# ATSAMA5D34 register map
Vendor: Atmel; Series: SAMA5D3; File version: 20130221
Registers are 32-bit, read-write, reset 0x0 unless marked. A register's access mark holds for its fields unless they carry their own. Offsets are from the block's base; [hi:lo] are bit positions; {n}, {i} and the like mark numbered series.

## TRNG — True Random Number Generator
Base 0xF8040000; register names take the prefix TRNG_
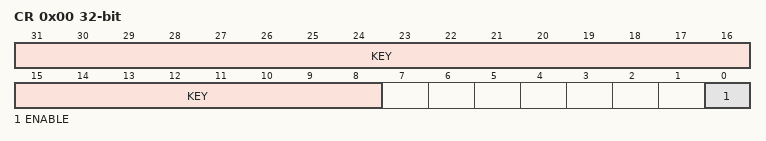
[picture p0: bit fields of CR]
0x00 CR wo reset not defined — Control Register
  [31:8] KEY — Security Key
  [0] ENABLE — Enables the TRNG to provide random values
0x10 IER wo reset not defined — Interrupt Enable Register
  [0] DATRDY — Data Ready Interrupt Enable
0x14 IDR wo reset not defined — Interrupt Disable Register
  [0] DATRDY — Data Ready Interrupt Disable
0x18 IMR ro — Interrupt Mask Register
  [0] DATRDY — Data Ready Interrupt Mask
0x1C ISR ro — Interrupt Status Register
  [0] DATRDY — Data Ready
0x50 ODATA ro — Output Data Register
  [31:0] ODATA — Output Data

## FUSE — Fuse Controller
Base 0xFFFFE400; register names take the prefix FUSE_
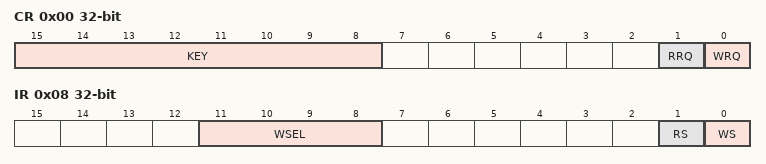
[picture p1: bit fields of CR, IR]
0x00 CR wo reset not defined — Fuse Control Register
  [15:8] KEY — Key code
    251=VALID (valid key.)
  [1] RRQ — Read Request
  [0] WRQ — Write Request
0x04 MR wo reset not defined — Fuse Mode Register
  [0] MSK — Mask Fuse Status Registers
0x08 IR — Fuse Index Register
  [11:8] WSEL — Word Selection
  [1] RS — Read Status
  [0] WS — Write Status
0x0C DR reset not defined — Fuse Data Register
  [31:0] DATA — Data to Program
{0x10+4i} SR[{i}] (i=0..7) ro reset not defined — Fuse Status Register
  [31:0] FUSE — Fuse Status

## MATRIX — AHB Bus Matrix
Base 0xFFFFEC00; register names take the prefix MATRIX_
{0x0+4i} MCFG[{i}] (i=0..15) reset not defined — Master Configuration Register
  [2:0] ULBT — Undefined Length Burst Type
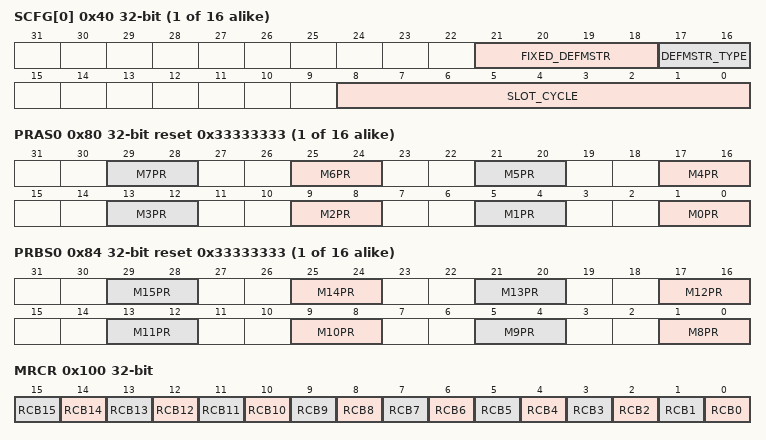
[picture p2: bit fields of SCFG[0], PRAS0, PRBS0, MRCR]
{0x40+4i} SCFG[{i}] (i=0..15) reset not defined — Slave Configuration Register
  [21:18] FIXED_DEFMSTR — Fixed Default Master
  [17:16] DEFMSTR_TYPE — Default Master Type
  [8:0] SLOT_CYCLE — Maximum Bus Grant Duration for Masters
{0x80+8i} PRAS{i} reset 0x33333333 (i=0..15) — Priority Register A for Slave {i}
  [4n+1:4n] M{n}PR (n=0..7) — Master {n} Priority
{0x84+8i} PRBS{i} reset 0x33333333 (i=0..15) — Priority Register B for Slave {i}
  [4n-31:4n-32] M{n}PR (n=8..15) — Master {n} Priority
0x100 MRCR — Master Remap Control Register
  [n] RCB{n} (n=0..15)
{0x110+4i} SFR[{i}] (i=0..15) reset not defined — Special Function Register
  [31:0] SFR — Special Function Register Fields
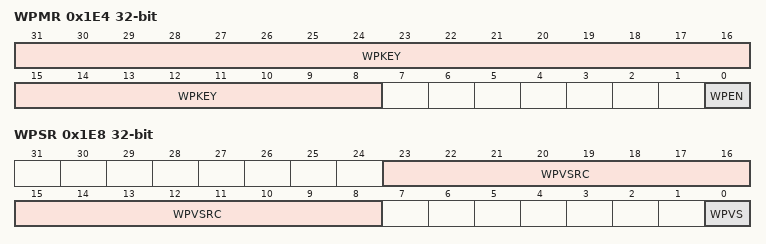
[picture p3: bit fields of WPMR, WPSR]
0x1E4 WPMR — Write Protect Mode Register
  [31:8] WPKEY — Write Protect KEY (Write-only)
  [0] WPEN — Write Protect Enable
0x1E8 WPSR ro — Write Protect Status Register
  [23:8] WPVSRC — Write Protect Violation Source
  [0] WPVS — Write Protect Violation Status

## AIC — Advanced Interrupt Controller
Base 0xFFFFF000; register names take the prefix AIC_
0x00 SSR — Source Select Register
  [6:0] INTSEL — Interrupt line Selection
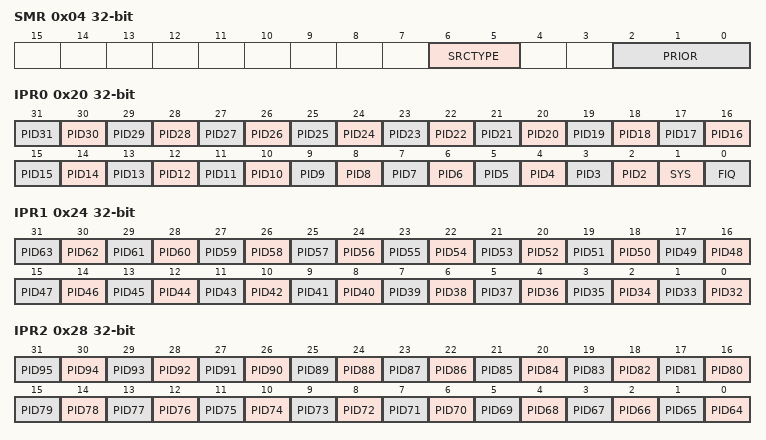
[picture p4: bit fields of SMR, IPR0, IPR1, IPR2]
0x04 SMR — Source Mode Register
  [6:5] SRCTYPE — Interrupt Source Type
    0=INT_LEVEL_SENSITIVE (High level Sensitive for internal sourceLow level Sensitive for external source); 1=INT_EDGE_TRIGGERED (Positive edge triggered for internal sourceNegative edge triggered for external source); 2=EXT_HIGH_LEVEL (High level Sensitive for internal sourceHigh level Sensitive for external source); 3=EXT_POSITIVE_EDGE (Positive edge triggered for internal sourcePositive edge triggered for external source)
  [2:0] PRIOR — Priority Level
0x08 SVR — Source Vector Register
  [31:0] VECTOR — Source Vector
0x10 IVR ro — Interrupt Vector Register
  [31:0] IRQV
0x14 FVR ro — FIQ Interrupt Vector Register
  [31:0] FIQV — FIQ Vector Register
0x18 ISR ro — Interrupt Status Register
  [6:0] IRQID — Current Interrupt Identifier
0x20 IPR0 ro — Interrupt Pending Register 0
  [n] PID{n} (n=2..31) — Interrupt Pending
  [1] SYS — Interrupt Pending
  [0] FIQ — Interrupt Pending
0x24 IPR1 ro — Interrupt Pending Register 1
  [n-32] PID{n} (n=32..63) — Interrupt Pending
0x28 IPR2 ro — Interrupt Pending Register 2
  [n-64] PID{n} (n=64..95) — Interrupt Pending
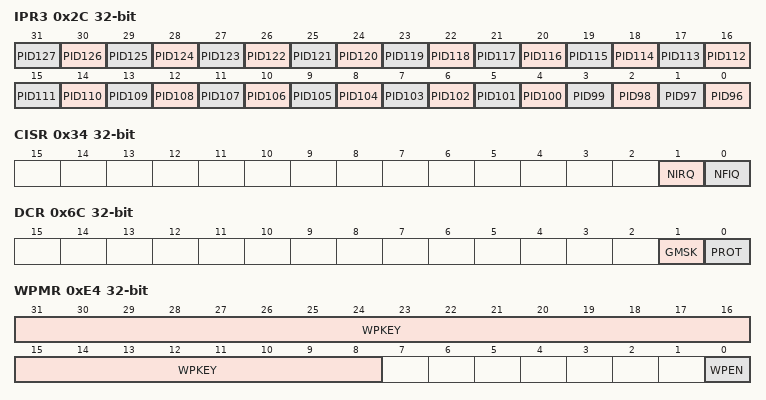
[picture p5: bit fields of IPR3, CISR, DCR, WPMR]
0x2C IPR3 ro — Interrupt Pending Register 3
  [n-96] PID{n} (n=96..127) — Interrupt Pending
0x30 IMR ro — Interrupt Mask Register
  [0] INTM — Interrupt Mask
0x34 CISR ro — Core Interrupt Status Register
  [1] NIRQ — NIRQ Status
  [0] NFIQ — NFIQ Status
0x38 EOICR wo reset not defined — End of Interrupt Command Register
  [0] ENDIT — Interrupt Processing Complete Command
0x3C SPU — Spurious Interrupt Vector Register
  [31:0] SIVR
0x40 IECR wo reset not defined — Interrupt Enable Command Register
  [0] INTEN — Interrupt Enable
0x44 IDCR wo reset not defined — Interrupt Disable Command Register
  [0] INTD — Interrupt Disable
0x48 ICCR wo reset not defined — Interrupt Clear Command Register
  [0] INTCLR — Interrupt Clear
0x4C ISCR wo reset not defined — Interrupt Set Command Register
  [0] INTSET — Interrupt Set
0x50 FFER wo reset not defined — Fast Forcing Enable Register
  [0] FFEN — Fast Forcing Enable
0x54 FFDR wo reset not defined — Fast Forcing Disable Register
  [0] FFDIS — Fast Forcing Disable
0x58 FFSR ro — Fast Forcing Status Register
  [0] FFS — Fast Forcing Status
0x6C DCR — Debug Control Register
  [1] GMSK — General Mask
  [0] PROT — Protection Mode
0xE4 WPMR — Write Protect Mode Register
  [31:8] WPKEY — Write Protect KEY
  [0] WPEN — Write Protect Enable
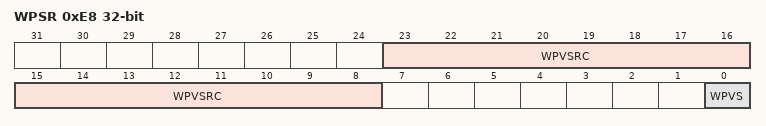
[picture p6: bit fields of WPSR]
0xE8 WPSR ro — Write Protect Status Register
  [23:8] WPVSRC — Write Protect Violation Source
  [0] WPVS — Write Protect Violation Status
